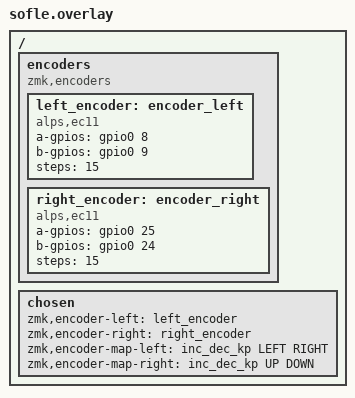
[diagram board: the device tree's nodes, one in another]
// 放置在 zmk/app/boards/shields/sofle/sofle.overlay
/ {
    encoders {
        compatible = "zmk,encoders";
        
        left_encoder: encoder_left {
            compatible = "alps,ec11";
            a-gpios = <&gpio0 8 (GPIO_ACTIVE_HIGH | GPIO_PULL_UP)>;
            b-gpios = <&gpio0 9 (GPIO_ACTIVE_HIGH | GPIO_PULL_UP)>;
            steps = <15>;
        };

        right_encoder: encoder_right {
            compatible = "alps,ec11";
            a-gpios = <&gpio0 25 (GPIO_ACTIVE_HIGH | GPIO_PULL_UP)>;
            b-gpios = <&gpio0 24 (GPIO_ACTIVE_HIGH | GPIO_PULL_UP)>;
            steps = <15>;
        };
    };

    chosen {
        zmk,encoder-left = <&left_encoder>;
        zmk,encoder-right = <&right_encoder>;
        zmk,encoder-map-left = < &inc_dec_kp LEFT RIGHT >;
        zmk,encoder-map-right = < &inc_dec_kp UP DOWN >;
    };
};
